# STM32F091CBT6 register map
File version: 1.0
Registers are 32-bit, access not given, reset 0x0 unless marked. A register's access mark holds for its fields unless they carry their own. Offsets are from the block's base; [hi:lo] are bit positions; {n}, {i} and the like mark numbered series.

## SYSCFGCOMP
Base 0x40010000
0x80 ITLINE0
  [0] WWDG
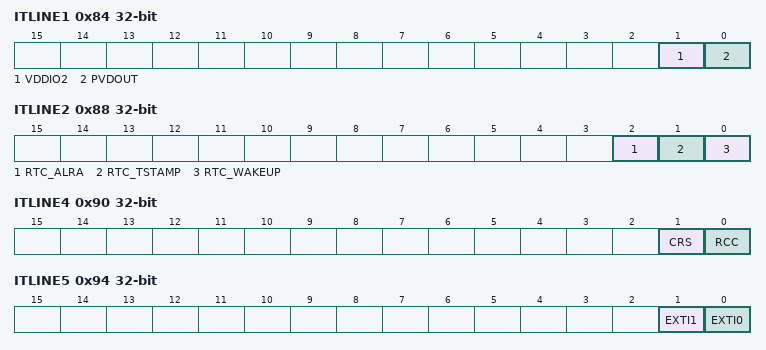
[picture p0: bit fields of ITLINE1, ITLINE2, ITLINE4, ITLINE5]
0x84 ITLINE1
  [1] VDDIO2, [0] PVDOUT
0x88 ITLINE2
  [2] RTC_ALRA, [1] RTC_TSTAMP, [0] RTC_WAKEUP
0x8C ITLINE3
  [0] FLASH_ITF
0x90 ITLINE4
  [1] CRS, [0] RCC
0x94 ITLINE5
  [1] EXTI1, [0] EXTI0
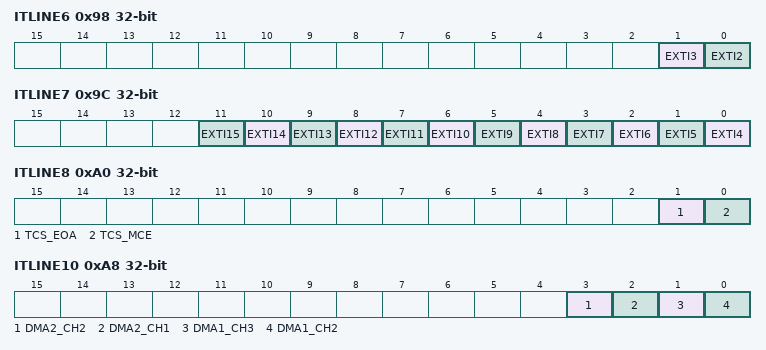
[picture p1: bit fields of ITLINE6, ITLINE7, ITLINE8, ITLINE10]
0x98 ITLINE6
  [1] EXTI3, [0] EXTI2
0x9C ITLINE7
  [n-4] EXTI{n} (n=4..15)
0xA0 ITLINE8
  [1] TCS_EOA, [0] TCS_MCE
0xA4 ITLINE9
  [0] DMA1_CH1
0xA8 ITLINE10
  [3] DMA2_CH2, [2] DMA2_CH1, [1] DMA1_CH3, [0] DMA1_CH2
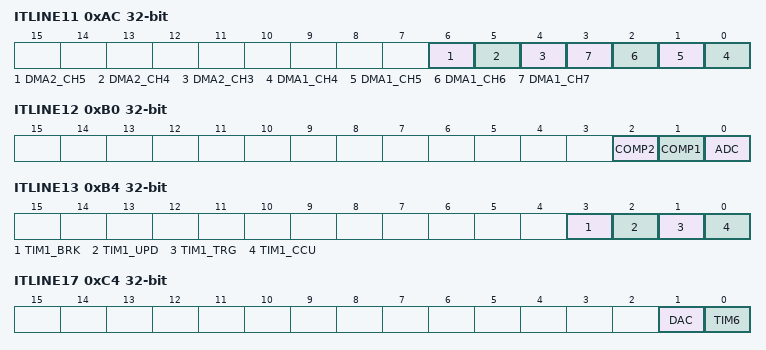
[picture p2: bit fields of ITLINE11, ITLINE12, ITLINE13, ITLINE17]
0xAC ITLINE11
  [6] DMA2_CH5, [5] DMA2_CH4, [4] DMA2_CH3, [n-4] DMA1_CH{n} (n=4..7)
0xB0 ITLINE12
  [2] COMP2, [1] COMP1, [0] ADC
0xB4 ITLINE13
  [3] TIM1_BRK, [2] TIM1_UPD, [1] TIM1_TRG, [0] TIM1_CCU
0xB8 ITLINE14
  [0] TIM1_CC
0xBC ITLINE15
  [0] TIM2
0xC0 ITLINE16
  [0] TIM3
0xC4 ITLINE17
  [1] DAC, [0] TIM6
0xC8 ITLINE18
  [0] TIM7
{0x80+4i} ITLINE{i} (i=19..22)
  [0] TIM{i-5}
0xDC ITLINE23
  [0] I2C1
0xE0 ITLINE24
  [0] I2C2
0xE4 ITLINE25
  [0] SPI1
0xE8 ITLINE26
  [0] SPI2
{0x80+4i} ITLINE{i} (i=27..29)
  [0] USART{i-26}
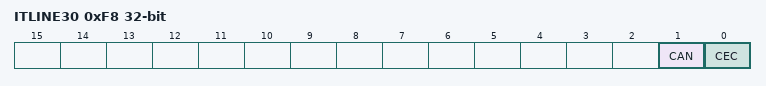
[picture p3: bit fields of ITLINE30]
0xF8 ITLINE30
  [1] CAN, [0] CEC

## EXTI
Base 0x40010400
0x00 IMR
  [31:0] IM
0x04 EMR
  [31:0] EM
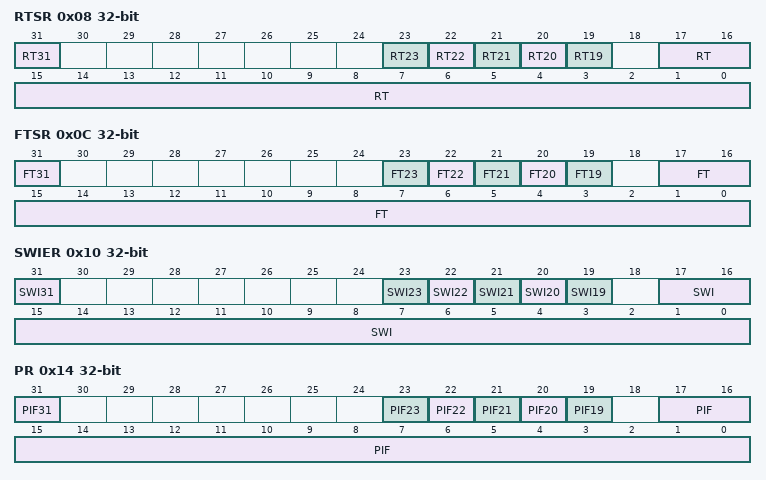
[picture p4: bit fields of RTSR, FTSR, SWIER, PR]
0x08 RTSR
  [31] RT31, [n] RT{n} (n=19..23), [17:0] RT
0x0C FTSR
  [31] FT31, [n] FT{n} (n=19..23), [17:0] FT
0x10 SWIER
  [31] SWI31, [n] SWI{n} (n=19..23), [17:0] SWI
0x14 PR
  [31] PIF31, [n] PIF{n} (n=19..23), [17:0] PIF

## ADC
Base 0x40012400
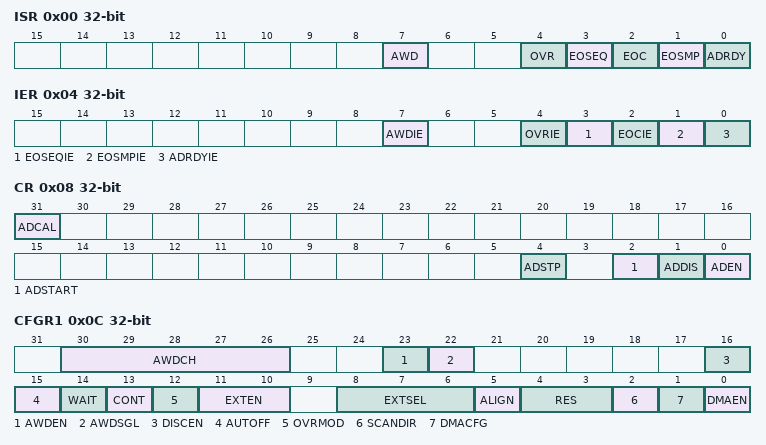
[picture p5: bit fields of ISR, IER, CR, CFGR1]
0x00 ISR
  [7] AWD, [4] OVR, [3] EOSEQ, [2] EOC, [1] EOSMP, [0] ADRDY
0x04 IER
  [7] AWDIE, [4] OVRIE, [3] EOSEQIE, [2] EOCIE, [1] EOSMPIE, [0] ADRDYIE
0x08 CR
  [31] ADCAL, [4] ADSTP, [2] ADSTART, [1] ADDIS, [0] ADEN
0x0C CFGR1
  [30:26] AWDCH, [23] AWDEN, [22] AWDSGL, [16] DISCEN, [15] AUTOFF, [14] WAIT, [13] CONT, [12] OVRMOD, [11:10] EXTEN, [8:6] EXTSEL, [5] ALIGN, [4:3] RES, [2] SCANDIR, [1] DMACFG, [0] DMAEN
0x10 CFGR2
  [31:30] CKMODE
0x14 SMPR
  [2:0] SMP
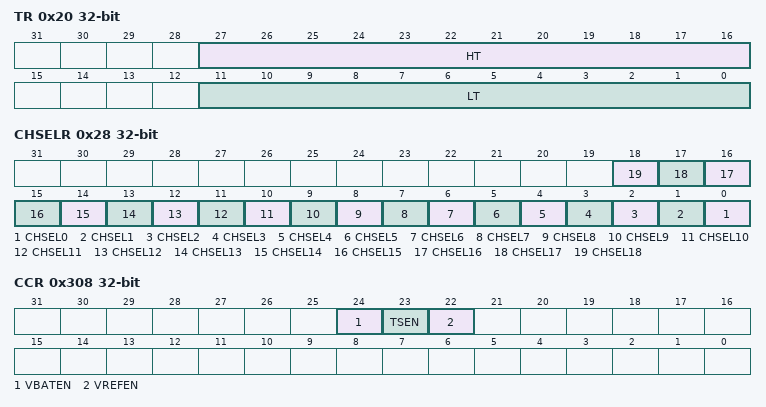
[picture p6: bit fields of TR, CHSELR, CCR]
0x20 TR
  [27:16] HT, [11:0] LT
0x28 CHSELR
  [n] CHSEL{n} (n=0..18)
0x40 DR
  [15:0] DATA
0x308 CCR
  [24] VBATEN, [23] TSEN, [22] VREFEN

## TIM1
Base 0x40012C00
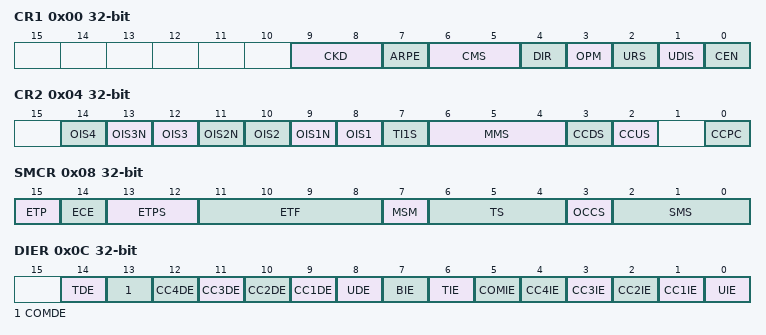
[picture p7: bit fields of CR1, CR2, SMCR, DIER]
0x00 CR1
  [9:8] CKD, [7] ARPE, [6:5] CMS, [4] DIR, [3] OPM, [2] URS, [1] UDIS, [0] CEN
0x04 CR2
  [2n+6] OIS{n} (n=1..4), [13] OIS3N, [11] OIS2N, [9] OIS1N, [7] TI1S, [6:4] MMS, [3] CCDS, [2] CCUS, [0] CCPC
0x08 SMCR
  [15] ETP, [14] ECE, [13:12] ETPS, [11:8] ETF, [7] MSM, [6:4] TS, [3] OCCS, [2:0] SMS
0x0C DIER
  [14] TDE, [13] COMDE, [n+8] CC{n}DE (n=1..4), [8] UDE, [7] BIE, [6] TIE, [5] COMIE, [n] CC{n}IE (n=1..4), [0] UIE
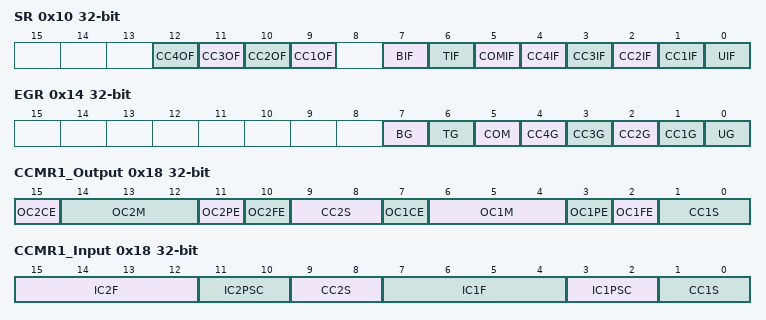
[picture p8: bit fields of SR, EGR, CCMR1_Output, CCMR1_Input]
0x10 SR
  [n+8] CC{n}OF (n=1..4), [7] BIF, [6] TIF, [5] COMIF, [n] CC{n}IF (n=1..4), [0] UIF
0x14 EGR
  [7] BG, [6] TG, [5] COM, [n] CC{n}G (n=1..4), [0] UG
0x18 CCMR1_Output
  [15] OC2CE, [14:12] OC2M, [11] OC2PE, [10] OC2FE, [9:8] CC2S, [7] OC1CE, [6:4] OC1M, [3] OC1PE, [2] OC1FE, [1:0] CC1S
0x18 CCMR1_Input
  [15:12] IC2F, [11:10] IC2PSC, [9:8] CC2S, [7:4] IC1F, [3:2] IC1PSC, [1:0] CC1S
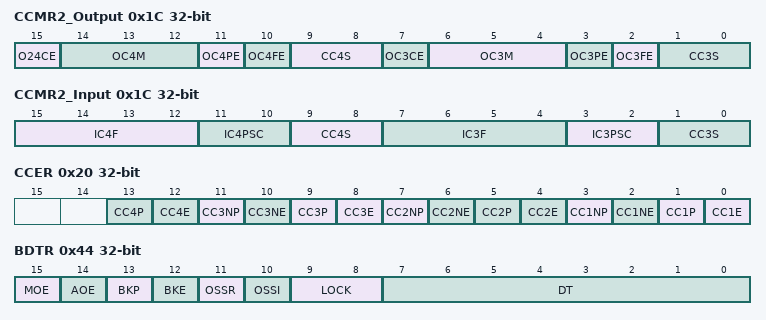
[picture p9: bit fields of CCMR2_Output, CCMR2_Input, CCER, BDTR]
0x1C CCMR2_Output
  [15] O24CE, [14:12] OC4M, [11] OC4PE, [10] OC4FE, [9:8] CC4S, [7] OC3CE, [6:4] OC3M, [3] OC3PE, [2] OC3FE, [1:0] CC3S
0x1C CCMR2_Input
  [15:12] IC4F, [11:10] IC4PSC, [9:8] CC4S, [7:4] IC3F, [3:2] IC3PSC, [1:0] CC3S
0x20 CCER
  [4n-3] CC{n}P (n=1..4), [4n-4] CC{n}E (n=1..4), [11] CC3NP, [10] CC3NE, [7] CC2NP, [6] CC2NE, [3] CC1NP, [2] CC1NE
0x24 CNT
  [15:0] CNT
0x28 PSC
  [15:0] PSC
0x2C ARR
  [15:0] ARR
0x30 RCR
  [7:0] REP
{0x30+4i} CCR{i} (i=1..4)
  [15:0] CCR{i}
0x44 BDTR
  [15] MOE, [14] AOE, [13] BKP, [12] BKE, [11] OSSR, [10] OSSI, [9:8] LOCK, [7:0] DT
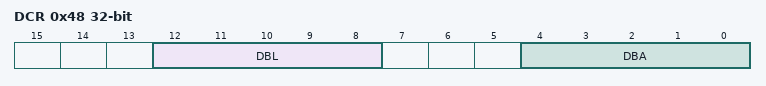
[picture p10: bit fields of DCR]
0x48 DCR
  [12:8] DBL, [4:0] DBA
0x4C DMAR
  [15:0] DMAB

## TIM15
Base 0x40014000
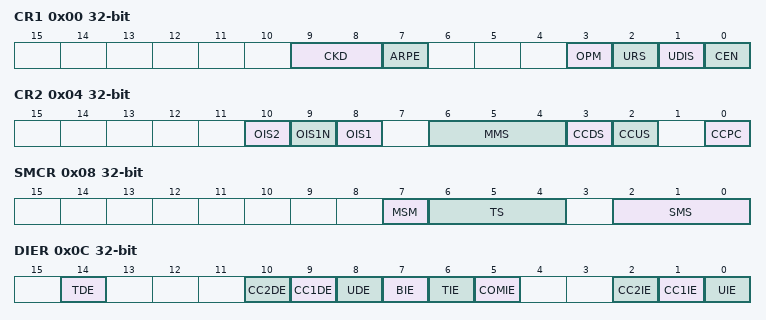
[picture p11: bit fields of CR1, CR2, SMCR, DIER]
0x00 CR1
  [9:8] CKD, [7] ARPE, [3] OPM, [2] URS, [1] UDIS, [0] CEN
0x04 CR2
  [10] OIS2, [9] OIS1N, [8] OIS1, [6:4] MMS, [3] CCDS, [2] CCUS, [0] CCPC
0x08 SMCR
  [7] MSM, [6:4] TS, [2:0] SMS
0x0C DIER
  [14] TDE, [10] CC2DE, [9] CC1DE, [8] UDE, [7] BIE, [6] TIE, [5] COMIE, [2] CC2IE, [1] CC1IE, [0] UIE
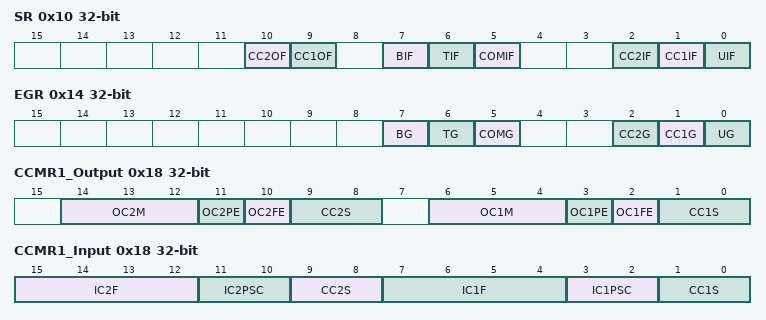
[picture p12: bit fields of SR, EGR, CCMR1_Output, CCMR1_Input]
0x10 SR
  [10] CC2OF, [9] CC1OF, [7] BIF, [6] TIF, [5] COMIF, [2] CC2IF, [1] CC1IF, [0] UIF
0x14 EGR
  [7] BG, [6] TG, [5] COMG, [2] CC2G, [1] CC1G, [0] UG
0x18 CCMR1_Output
  [14:12] OC2M, [11] OC2PE, [10] OC2FE, [9:8] CC2S, [6:4] OC1M, [3] OC1PE, [2] OC1FE, [1:0] CC1S
0x18 CCMR1_Input
  [15:12] IC2F, [11:10] IC2PSC, [9:8] CC2S, [7:4] IC1F, [3:2] IC1PSC, [1:0] CC1S
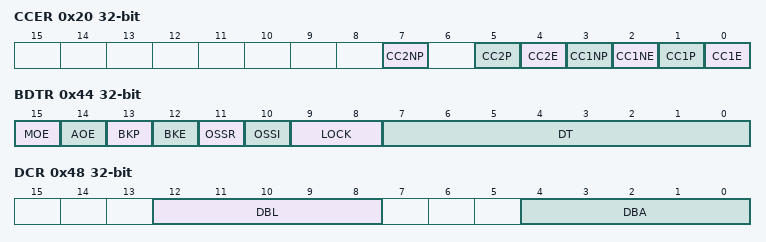
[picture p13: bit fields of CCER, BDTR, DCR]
0x20 CCER
  [7] CC2NP, [5] CC2P, [4] CC2E, [3] CC1NP, [2] CC1NE, [1] CC1P, [0] CC1E
0x24 CNT
  [15:0] CNT
0x28 PSC
  [15:0] PSC
0x2C ARR
  [15:0] ARR
0x30 RCR
  [7:0] REP
0x34 CCR1
  [15:0] CCR1
0x38 CCR2
  [15:0] CCR2
0x44 BDTR
  [15] MOE, [14] AOE, [13] BKP, [12] BKE, [11] OSSR, [10] OSSI, [9:8] LOCK, [7:0] DT
0x48 DCR
  [12:8] DBL, [4:0] DBA
0x4C DMAR
  [15:0] DMAB
